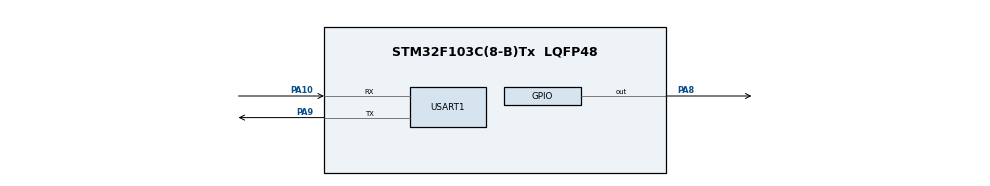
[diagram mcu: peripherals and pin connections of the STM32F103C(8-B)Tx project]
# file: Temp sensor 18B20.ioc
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Mcu.Family=STM32F1
Mcu.Name=STM32F103C(8-B)Tx
Mcu.Package=LQFP48
NVIC.PriorityGroup=NVIC_PRIORITYGROUP_4
PA10.Mode=Asynchronous
PA10.Signal=USART1_RX
PA13.Mode=Serial_Wire
PA13.Signal=SYS_JTMS-SWDIO
PA14.Mode=Serial_Wire
PA14.Signal=SYS_JTCK-SWCLK
PA8.Signal=GPIO_Output
PA9.Mode=Asynchronous
PA9.Signal=USART1_TX
PD0-OSC_IN.Mode=HSE-External-Oscillator
PD0-OSC_IN.Signal=RCC_OSC_IN
PD1-OSC_OUT.Mode=HSE-External-Oscillator
PD1-OSC_OUT.Signal=RCC_OSC_OUT
ProjectManager.HeapSize=0x200
ProjectManager.StackSize=0x400
ProjectManager.TargetToolchain=MDK-ARM V5.27
RCC.AHBFreq_Value=72000000
RCC.APB1CLKDivider=RCC_HCLK_DIV2
RCC.APB1Freq_Value=36000000
RCC.APB1TimFreq_Value=72000000
RCC.APB2Freq_Value=72000000
RCC.APB2TimFreq_Value=72000000
RCC.HCLKFreq_Value=72000000
RCC.PLLMUL=RCC_PLL_MUL9
RCC.PLLSourceVirtual=RCC_PLLSOURCE_HSE
RCC.SYSCLKFreq_VALUE=72000000
RCC.SYSCLKSource=RCC_SYSCLKSOURCE_PLLCLK
RCC.USBFreq_Value=72000000
TIM1.Prescaler=71
USART1.VirtualMode=VM_ASYNC
VP_TIM1_VS_ClockSourceINT.Mode=Internal
board=custom

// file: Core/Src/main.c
/* USER CODE BEGIN Header */
/**
  ******************************************************************************
  * @file           : main.c
  * @brief          : Main program body
  ******************************************************************************
  * @attention
  *
  * <h2><center>&copy; Copyright (c) 2022 STMicroelectronics.
  * All rights reserved.</center></h2>
  *
  * This software component is licensed by ST under BSD 3-Clause license,
  * the "License"; You may not use this file except in compliance with the
  * License. You may obtain a copy of the License at:
  *                        opensource.org/licenses/BSD-3-Clause
  *
  ******************************************************************************
  */
/* USER CODE END Header */
#include "main.h"

/* USER CODE BEGIN Includes */
#include "stdio_usart1.h"
//#include "onewire.h"
#include "DS18B20.h"
/* USER CODE END Includes */

void SystemClock_Config(void);
static void MX_GPIO_Init(void);
static void MX_TIM1_Init(void);
static void MX_USART1_UART_Init(void);

int main(void)
{

  /* MCU Configuration--------------------------------------------------------*/

  /* Reset of all peripherals, Initializes the Flash interface and the Systick. */

  LL_APB2_GRP1_EnableClock(LL_APB2_GRP1_PERIPH_AFIO);
  LL_APB1_GRP1_EnableClock(LL_APB1_GRP1_PERIPH_PWR);

  NVIC_SetPriorityGrouping(NVIC_PRIORITYGROUP_4);

  /* System interrupt init*/

  /** NOJTAG: JTAG-DP Disabled and SW-DP Enabled
  */
  LL_GPIO_AF_Remap_SWJ_NOJTAG();

  /* Configure the system clock */
  SystemClock_Config();

  /* Initialize all configured peripherals */
  MX_GPIO_Init();
  MX_TIM1_Init();
  MX_USART1_UART_Init();

  /* Infinite loop */
  while (1)
  {

    /* USER CODE BEGIN 3 */

			float temp = DS18B20_Convert();		// Get temperature
			printf("%f\r\n", temp);						// Print temerature
			LL_mDelay(1000);
  }
  /* USER CODE END 3 */
}

void SystemClock_Config(void)
{
  LL_FLASH_SetLatency(LL_FLASH_LATENCY_2);
  while(LL_FLASH_GetLatency()!= LL_FLASH_LATENCY_2)
  {
  }
  LL_RCC_HSE_Enable();

   /* Wait till HSE is ready */
  while(LL_RCC_HSE_IsReady() != 1)
  {

  }
  LL_RCC_PLL_ConfigDomain_SYS(LL_RCC_PLLSOURCE_HSE_DIV_1, LL_RCC_PLL_MUL_9);
  LL_RCC_PLL_Enable();

   /* Wait till PLL is ready */
  while(LL_RCC_PLL_IsReady() != 1)
  {

  }
  LL_RCC_SetAHBPrescaler(LL_RCC_SYSCLK_DIV_1);
  LL_RCC_SetAPB1Prescaler(LL_RCC_APB1_DIV_2);
  LL_RCC_SetAPB2Prescaler(LL_RCC_APB2_DIV_1);
  LL_RCC_SetSysClkSource(LL_RCC_SYS_CLKSOURCE_PLL);

   /* Wait till System clock is ready */
  while(LL_RCC_GetSysClkSource() != LL_RCC_SYS_CLKSOURCE_STATUS_PLL)
  {

  }
  LL_Init1msTick(72000000);
  LL_SetSystemCoreClock(72000000);
}

static void MX_TIM1_Init(void)
{

  LL_TIM_InitTypeDef TIM_InitStruct = {0};

  /* Peripheral clock enable */
  LL_APB2_GRP1_EnableClock(LL_APB2_GRP1_PERIPH_TIM1);

  TIM_InitStruct.Prescaler = 71;
  TIM_InitStruct.CounterMode = LL_TIM_COUNTERMODE_UP;
  TIM_InitStruct.Autoreload = 65535;
  TIM_InitStruct.ClockDivision = LL_TIM_CLOCKDIVISION_DIV1;
  TIM_InitStruct.RepetitionCounter = 0;
  LL_TIM_Init(TIM1, &TIM_InitStruct);
  LL_TIM_DisableARRPreload(TIM1);
  LL_TIM_SetClockSource(TIM1, LL_TIM_CLOCKSOURCE_INTERNAL);
  LL_TIM_SetTriggerOutput(TIM1, LL_TIM_TRGO_RESET);
  LL_TIM_DisableMasterSlaveMode(TIM1);

}

static void MX_USART1_UART_Init(void)
{

  LL_USART_InitTypeDef USART_InitStruct = {0};

  LL_GPIO_InitTypeDef GPIO_InitStruct = {0};

  /* Peripheral clock enable */
  LL_APB2_GRP1_EnableClock(LL_APB2_GRP1_PERIPH_USART1);

  LL_APB2_GRP1_EnableClock(LL_APB2_GRP1_PERIPH_GPIOA);
  /**USART1 GPIO Configuration
  PA9   ------> USART1_TX
  PA10   ------> USART1_RX
  */
  GPIO_InitStruct.Pin = LL_GPIO_PIN_9;
  GPIO_InitStruct.Mode = LL_GPIO_MODE_ALTERNATE;
  GPIO_InitStruct.Speed = LL_GPIO_SPEED_FREQ_HIGH;
  GPIO_InitStruct.OutputType = LL_GPIO_OUTPUT_PUSHPULL;
  LL_GPIO_Init(GPIOA, &GPIO_InitStruct);

  GPIO_InitStruct.Pin = LL_GPIO_PIN_10;
  GPIO_InitStruct.Mode = LL_GPIO_MODE_FLOATING;
  LL_GPIO_Init(GPIOA, &GPIO_InitStruct);

  USART_InitStruct.BaudRate = 115200;
  USART_InitStruct.DataWidth = LL_USART_DATAWIDTH_8B;
  USART_InitStruct.StopBits = LL_USART_STOPBITS_1;
  USART_InitStruct.Parity = LL_USART_PARITY_NONE;
  USART_InitStruct.TransferDirection = LL_USART_DIRECTION_TX_RX;
  USART_InitStruct.HardwareFlowControl = LL_USART_HWCONTROL_NONE;
  USART_InitStruct.OverSampling = LL_USART_OVERSAMPLING_16;
  LL_USART_Init(USART1, &USART_InitStruct);
  LL_USART_ConfigAsyncMode(USART1);
  LL_USART_Enable(USART1);

}

static void MX_GPIO_Init(void)
{
  LL_GPIO_InitTypeDef GPIO_InitStruct = {0};

  /* GPIO Ports Clock Enable */
  LL_APB2_GRP1_EnableClock(LL_APB2_GRP1_PERIPH_GPIOD);
  LL_APB2_GRP1_EnableClock(LL_APB2_GRP1_PERIPH_GPIOA);

  /**/
  LL_GPIO_ResetOutputPin(GPIOA, LL_GPIO_PIN_8);

  /**/
  GPIO_InitStruct.Pin = LL_GPIO_PIN_8;
  GPIO_InitStruct.Mode = LL_GPIO_MODE_OUTPUT;
  GPIO_InitStruct.Speed = LL_GPIO_SPEED_FREQ_HIGH;
  GPIO_InitStruct.OutputType = LL_GPIO_OUTPUT_OPENDRAIN;
  LL_GPIO_Init(GPIOA, &GPIO_InitStruct);

}

void Error_Handler(void)
{
  __disable_irq();
  while (1)
  {
  }
}

/************************ (C) COPYRIGHT STMicroelectronics *****END OF FILE****/
